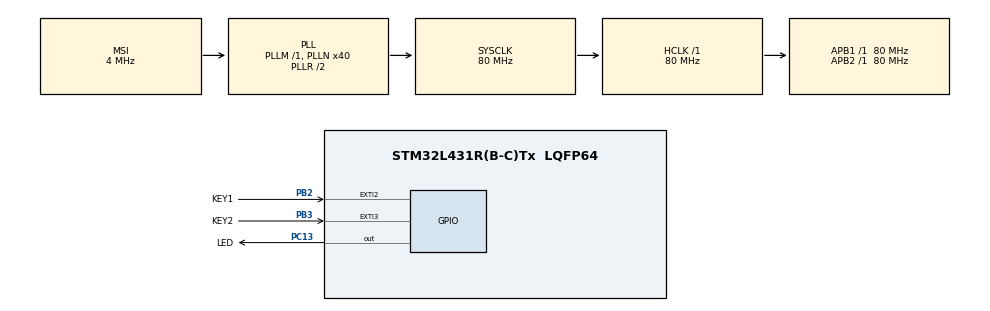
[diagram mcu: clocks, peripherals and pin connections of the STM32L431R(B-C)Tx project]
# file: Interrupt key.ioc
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Mcu.Family=STM32L4
Mcu.Name=STM32L431R(B-C)Tx
Mcu.Package=LQFP64
NVIC.EXTI2_IRQn=true\:0\:0\:false\:false\:true\:true\:true
NVIC.EXTI3_IRQn=true\:0\:0\:false\:false\:true\:true\:true
NVIC.PriorityGroup=NVIC_PRIORITYGROUP_4
PB2.GPIO_Label=KEY1
PB2.GPIO_ModeDefaultEXTI=GPIO_MODE_IT_FALLING
PB2.GPIO_PuPd=GPIO_PULLUP
PB2.Signal=GPXTI2
PB3\ (JTDO-TRACESWO).GPIO_Label=KEY2
PB3\ (JTDO-TRACESWO).GPIO_ModeDefaultEXTI=GPIO_MODE_IT_FALLING
PB3\ (JTDO-TRACESWO).GPIO_PuPd=GPIO_PULLUP
PB3\ (JTDO-TRACESWO).Signal=GPXTI3
PC13.GPIO_Label=LED
PC13.Signal=GPIO_Output
ProjectManager.HeapSize=0x200
ProjectManager.StackSize=0x400
ProjectManager.TargetToolchain=MDK-ARM V5.32
RCC.AHBFreq_Value=80000000
RCC.APB1Freq_Value=80000000
RCC.APB1TimFreq_Value=80000000
RCC.APB2Freq_Value=80000000
RCC.APB2TimFreq_Value=80000000
RCC.CortexFreq_Value=80000000
RCC.HCLKFreq_Value=80000000
RCC.HSE_VALUE=8000000
RCC.HSI48_VALUE=48000000
RCC.HSI_VALUE=16000000
RCC.LSE_VALUE=32768
RCC.MSI_VALUE=4000000
RCC.PLLN=40
RCC.SYSCLKFreq_VALUE=80000000
RCC.SYSCLKSource=RCC_SYSCLKSOURCE_PLLCLK
RCC.VCOOutputFreq_Value=160000000
board=custom

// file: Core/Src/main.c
/* USER CODE BEGIN Header */
/**
  ******************************************************************************
  * @file           : main.c
  * @brief          : Main program body
  ******************************************************************************
  * @attention
  *
  * <h2><center>&copy; Copyright (c) 2021 STMicroelectronics.
  * All rights reserved.</center></h2>
  *
  * This software component is licensed by ST under BSD 3-Clause license,
  * the "License"; You may not use this file except in compliance with the
  * License. You may obtain a copy of the License at:
  *                        opensource.org/licenses/BSD-3-Clause
  *
  ******************************************************************************
  */
/* USER CODE END Header */
#include "main.h"
#include "gpio.h"

enum Led_Mode_Value{
	flashingmode = 0, //闪烁模式
	breathMode = 1, //呼吸灯模式
	lightMode = 2,  //常亮模式
	extinctMode = 3 //熄灭LED模式
	} Led_Mode = lightMode;//将初始模式设置为常亮模式

void SystemClock_Config(void);
/* USER CODE BEGIN PFP */
void delay_us(uint32_t us);//
/* USER CODE END PFP */

int main(void)
{

  /* MCU Configuration--------------------------------------------------------*/

  /* Reset of all peripherals, Initializes the Flash interface and the Systick. */
  HAL_Init();

  /* Configure the system clock */
  SystemClock_Config();

  /* Initialize all configured peripherals */
  MX_GPIO_Init();

  /* Infinite loop */
  /* USER CODE BEGIN WHILE */
  while (1)
  {
    //LED常亮
		if(Led_Mode == lightMode)
		{
			HAL_GPIO_WritePin(LED_GPIO_Port,LED_Pin,GPIO_PIN_SET);//LED亮
		}

		//LED闪烁
		if(Led_Mode == flashingmode)
		{
			HAL_GPIO_TogglePin(LED_GPIO_Port, LED_Pin);
			HAL_Delay(500);
		}

		//LED熄灭
		if(Led_Mode == extinctMode)
		{
			HAL_GPIO_WritePin(LED_GPIO_Port,LED_Pin,GPIO_PIN_RESET);//LED亮
		}
		/* USER CODE END WHILE */

    /* USER CODE BEGIN 3 */
		//LED呼吸灯
		if(Led_Mode == breathMode)
		{
			for(int timeCount = 0, changetime = -200; Led_Mode == breathMode;)
			{
				for(int timeCount2 = 0; timeCount2 < 10; timeCount2++)
				{
					HAL_GPIO_WritePin(LED_GPIO_Port, LED_Pin, GPIO_PIN_SET);
					delay_us(timeCount/10);
					HAL_GPIO_WritePin(LED_GPIO_Port, LED_Pin, GPIO_PIN_RESET);
					delay_us(2000-timeCount/10);
				}
				if(timeCount>=20000||timeCount<=0)
				{
					changetime = -changetime;
				}
				timeCount+=changetime;
			}
		}
  }
  /* USER CODE END 3 */
}

void SystemClock_Config(void)
{
  RCC_OscInitTypeDef RCC_OscInitStruct = {0};
  RCC_ClkInitTypeDef RCC_ClkInitStruct = {0};

  /** Configure the main internal regulator output voltage
  */
  if (HAL_PWREx_ControlVoltageScaling(PWR_REGULATOR_VOLTAGE_SCALE1) != HAL_OK)
  {
    Error_Handler();
  }
  /** Initializes the RCC Oscillators according to the specified parameters
  * in the RCC_OscInitTypeDef structure.
  */
  RCC_OscInitStruct.OscillatorType = RCC_OSCILLATORTYPE_MSI;
  RCC_OscInitStruct.MSIState = RCC_MSI_ON;
  RCC_OscInitStruct.MSICalibrationValue = 0;
  RCC_OscInitStruct.MSIClockRange = RCC_MSIRANGE_6;
  RCC_OscInitStruct.PLL.PLLState = RCC_PLL_ON;
  RCC_OscInitStruct.PLL.PLLSource = RCC_PLLSOURCE_MSI;
  RCC_OscInitStruct.PLL.PLLM = 1;
  RCC_OscInitStruct.PLL.PLLN = 40;
  RCC_OscInitStruct.PLL.PLLP = RCC_PLLP_DIV7;
  RCC_OscInitStruct.PLL.PLLQ = RCC_PLLQ_DIV2;
  RCC_OscInitStruct.PLL.PLLR = RCC_PLLR_DIV2;
  if (HAL_RCC_OscConfig(&RCC_OscInitStruct) != HAL_OK)
  {
    Error_Handler();
  }
  /** Initializes the CPU, AHB and APB buses clocks
  */
  RCC_ClkInitStruct.ClockType = RCC_CLOCKTYPE_HCLK|RCC_CLOCKTYPE_SYSCLK
                              |RCC_CLOCKTYPE_PCLK1|RCC_CLOCKTYPE_PCLK2;
  RCC_ClkInitStruct.SYSCLKSource = RCC_SYSCLKSOURCE_PLLCLK;
  RCC_ClkInitStruct.AHBCLKDivider = RCC_SYSCLK_DIV1;
  RCC_ClkInitStruct.APB1CLKDivider = RCC_HCLK_DIV1;
  RCC_ClkInitStruct.APB2CLKDivider = RCC_HCLK_DIV1;

  if (HAL_RCC_ClockConfig(&RCC_ClkInitStruct, FLASH_LATENCY_4) != HAL_OK)
  {
    Error_Handler();
  }
}

/* USER CODE BEGIN 4 */
//中断回调函数
void HAL_GPIO_EXTI_Callback(uint16_t GPIO_Pin)
{
	if(GPIO_Pin == KEY1_Pin)
	{//按键KEY1控制LED模式
	 if(Led_Mode == lightMode)
		{//若当前模式为常亮，则再按下按键下一个模式为闪烁
			Led_Mode = flashingmode;
		}
		else if(Led_Mode == flashingmode)
		{//若当前模式为闪烁，则再按下按键下一个模式为呼吸灯
			Led_Mode = breathMode;
		}
		else if(Led_Mode == breathMode)
		{//若当前模式为呼吸灯，则再按下按键下一个模式为常亮
			Led_Mode = lightMode;
		}
		else if(Led_Mode == extinctMode)
			{//若当前模式为熄灭，则再按下按键下一个模式为常亮
			Led_Mode = lightMode;
		}
	}
	if(GPIO_Pin == KEY2_Pin)
	{//按键KEY2将LED熄灭，extinctMode
		if(Led_Mode == lightMode || Led_Mode == flashingmode || Led_Mode == breathMode)
		{
			Led_Mode = extinctMode;
		}
	}
}

void delay_us(uint32_t us)
{
    uint32_t delay = (HAL_RCC_GetHCLKFreq() / 4000000 * us);
    while (delay--)
	{
		;
	}
}
/* USER CODE END 4 */

void Error_Handler(void)
{
  __disable_irq();
  while (1)
  {
  }
}

/************************ (C) COPYRIGHT STMicroelectronics *****END OF FILE****/
